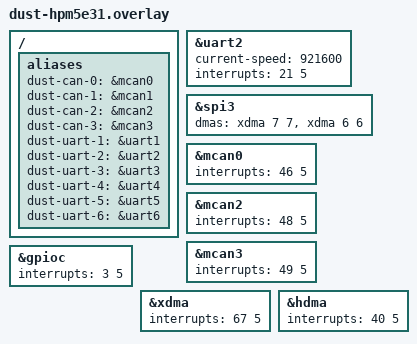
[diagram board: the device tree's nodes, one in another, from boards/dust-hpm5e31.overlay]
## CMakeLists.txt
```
# SPDX-License-Identifier: Apache-2.0

cmake_minimum_required(VERSION 3.20.0)

# ==============================================================================
# 1. Project Initialization
# ==============================================================================

include(${CMAKE_CURRENT_LIST_DIR}/cmake/prepare.cmake)

find_package(Zephyr REQUIRED HINTS $ENV{ZEPHYR_BASE})
project(dust_ethercat_slave)


set(CMAKE_EXPORT_COMPILE_COMMANDS ON)

# ==============================================================================
# 2. Paths and Dependencies
# ==============================================================================

set(ADAPTER_SSC_DIR
    "${ADAPTER_ROOT}/src/ssc_generated"
    CACHE PATH "Licensed SSC 5.13 generated source directory"
)

set(HPM_PHY_DIR
    "${HPM_SUPPORT_DIR}/samples/ecat/Middleware/ESC"
)
set(HPM_PHY_BOARD_DIR
    "${HPM_SUPPORT_DIR}/samples/ecat/EtherCAT/bsp"
)

set(GENERATED_DIR "${CMAKE_CURRENT_BINARY_DIR}/generated")
set(SSC_GATEWAY_DIR "${CMAKE_CURRENT_BINARY_DIR}/ssc_gateway")
set(ADAPTER_CAN_CONFIG
    "${ADAPTER_ROOT}/config/can_devices.yaml"
    CACHE FILEPATH "MCU CAN device/protection configuration"
)
if(CONFIG_ECAT_CAN_ISOLATION)
    # Keep the diagnostic topology and protection whitelist inseparable.
    set(ADAPTER_CAN_CONFIG "${ADAPTER_ROOT}/config/can_isolation.yaml")
endif()
set(PDO_SCHEMA "${ADAPTER_ROOT}/config/pdo_schema.yaml")

find_package(Python3 COMPONENTS Interpreter REQUIRED)

# ==============================================================================
# 3. Dependency Validation
# ==============================================================================

set(SSC_REQUIRED_FILES
    ecat_def.h
    ecatslv.c
    ecatappl.c
    sampleappl.c
    sampleappl.h
    applInterface.h
    eeprom.h
)
foreach(required_file IN LISTS SSC_REQUIRED_FILES)
    if(NOT EXISTS "${ADAPTER_SSC_DIR}/${required_file}")
        message(FATAL_ERROR
            "SSC source missing: ${required_file}. "
            "Import your licensed configured sources with tools/import_ssc.py; "
            "see docs/ethercat.md")
    endif()
endforeach()

file(READ "${ADAPTER_SSC_DIR}/ecat_def.h" SSC_CONFIG_CONTENT)
if(SSC_CONFIG_CONTENT MATCHES "#define[ \t]+DC_SUPPORTED[ \t]+1")
    message(FATAL_ERROR "FreeRun requires DC_SUPPORTED=0 SSC sources")
endif()

if(NOT EXISTS "${HPM_PHY_DIR}/hpm5e31_phy.c")
    message(FATAL_ERROR
        "HPM5E31 PHY implementation missing; update hpm_support to west.yml "
        "revision")
endif()

# ==============================================================================
# 4. Code Generation（构建期生成，生成物是常量唯一来源）
# ==============================================================================

file(MAKE_DIRECTORY "${GENERATED_DIR}" "${SSC_GATEWAY_DIR}")

set(PDO_SCHEMA_HEADER "${GENERATED_DIR}/pdo_schema.hpp")
add_custom_command(
    OUTPUT "${PDO_SCHEMA_HEADER}"
    COMMAND ${Python3_EXECUTABLE} "${ADAPTER_ROOT}/tools/generate_pdo_schema.py"
            --schema "${PDO_SCHEMA}" --output "${PDO_SCHEMA_HEADER}"
    DEPENDS "${ADAPTER_ROOT}/tools/generate_pdo_schema.py" "${PDO_SCHEMA}"
    COMMENT "Generating pdo_schema.hpp"
    VERBATIM)

set(CAN_PROFILE_HEADER "${GENERATED_DIR}/can_profile_generated.hpp")
add_custom_command(
    OUTPUT "${CAN_PROFILE_HEADER}"
    COMMAND ${Python3_EXECUTABLE} "${ADAPTER_ROOT}/tools/generate_can_profile.py"
            --input "${ADAPTER_CAN_CONFIG}" --output "${CAN_PROFILE_HEADER}"
    DEPENDS "${ADAPTER_ROOT}/tools/generate_can_profile.py"
            "${ADAPTER_CAN_CONFIG}"
    COMMENT "Generating can_profile_generated.hpp"
    VERBATIM)

add_custom_target(dust_pdo_schema DEPENDS "${PDO_SCHEMA_HEADER}")
add_custom_target(dust_can_profile DEPENDS "${CAN_PROFILE_HEADER}")

set_property(DIRECTORY APPEND PROPERTY CMAKE_CONFIGURE_DEPENDS
    "${ADAPTER_ROOT}/config/ethercat_gateway.json"
    "${ADAPTER_ROOT}/tools/generate_gateway_esi.py")
execute_process(
    COMMAND ${Python3_EXECUTABLE} "${ADAPTER_ROOT}/tools/generate_gateway_esi.py"
            --output "${SSC_GATEWAY_DIR}"
    COMMAND_ERROR_IS_FATAL ANY)

# ==============================================================================
# 5. SSC Source Staging
# ==============================================================================

file(GLOB SSC_INPUTS CONFIGURE_DEPENDS
    "${ADAPTER_SSC_DIR}/*.c" "${ADAPTER_SSC_DIR}/*.h")
set(SSC_SOURCES)
set(SSC_EXCLUDED_FILES sampleappl.c sampleappl.h eeprom.h)
foreach(input_file IN LISTS SSC_INPUTS)
    get_filename_component(file_name "${input_file}" NAME)
    if(file_name IN_LIST SSC_EXCLUDED_FILES)
        continue()
    endif()
    configure_file("${input_file}" "${SSC_GATEWAY_DIR}/${file_name}" COPYONLY)
    if(file_name MATCHES "\\.c$")
        list(APPEND SSC_SOURCES "${SSC_GATEWAY_DIR}/${file_name}")
    endif()
endforeach()
configure_file("${ADAPTER_ROOT}/src/adapters/ethercat_ssc/sampleappl.h"
               "${SSC_GATEWAY_DIR}/sampleappl.h" COPYONLY)

# ==============================================================================
# 6. Layered Static Libraries（依赖方向由链接图强制）
# ==============================================================================

# 6.1 domain: 协议/策略逻辑，链接 Zephyr 接口以统一 libc/stdint 配置。
add_library(dust_domain OBJECT
    "${ADAPTER_ROOT}/src/domain/protocol/wire.cpp"
    "${ADAPTER_ROOT}/src/domain/protocol/can_channel.cpp"
    "${ADAPTER_ROOT}/src/domain/protocol/uart_channel.cpp"
    "${ADAPTER_ROOT}/src/domain/protocol/codec.cpp"
    "${ADAPTER_ROOT}/src/domain/pdo/layout.cpp"
    "${ADAPTER_ROOT}/src/domain/pdo/pdo_dictionary.cpp"
    "${ADAPTER_ROOT}/src/domain/protocol/session.cpp"
    "${ADAPTER_ROOT}/src/domain/can/can_service.cpp"
    "${ADAPTER_ROOT}/src/domain/uart/uart_service.cpp"
    "${ADAPTER_ROOT}/src/domain/protection/protection.cpp"
)
target_include_directories(dust_domain
    PUBLIC "${ADAPTER_ROOT}/src"
    PRIVATE "${GENERATED_DIR}")
target_compile_features(dust_domain PUBLIC cxx_std_17)
target_compile_options(dust_domain PRIVATE -fno-exceptions -fno-rtti)
# 统一 libc/stdint 配置：与 app/adapters 使用同一套 stdint 定义。
target_link_libraries(dust_domain PRIVATE zephyr_interface)
add_dependencies(dust_domain dust_pdo_schema)

# 6.2 drivers: 窄硬件原语 + CAN/UART/IMU 设备类。
add_library(dust_drivers OBJECT
    "${ADAPTER_ROOT}/src/drivers/can/can_driver.cpp"
    "${ADAPTER_ROOT}/src/drivers/uart/uart_driver.cpp"
    "${ADAPTER_ROOT}/src/drivers/uart/uart_receive.cpp"
    "${ADAPTER_ROOT}/src/drivers/spi_imu/imu_sensor.cpp"
    "${ADAPTER_ROOT}/src/drivers/spi_imu/imu_source.cpp"
    "${ADAPTER_ROOT}/src/drivers/can/can_bus.cpp"
    "${ADAPTER_ROOT}/src/drivers/uart/uart_port.cpp"
    "${ADAPTER_ROOT}/src/drivers/pwm/outputs.cpp"
)
if(CONFIG_BUZZER OR CONFIG_BOARD_OUTPUTS)
    target_sources(dust_drivers PRIVATE
        "${ADAPTER_ROOT}/src/drivers/pwm/board_pwm.c")
endif()
if(CONFIG_BUZZER)
    target_sources(dust_drivers PRIVATE
        "${ADAPTER_ROOT}/src/drivers/pwm/buzzer.c")
endif()
target_include_directories(dust_drivers PUBLIC "${ADAPTER_ROOT}/src")
target_link_libraries(dust_drivers PRIVATE zephyr_interface)

# 6.3 adapters: ESC/SSC/board 适配。
add_library(dust_adapters OBJECT
    "${ADAPTER_ROOT}/src/adapters/esc/esc_regs.c"
    "${ADAPTER_ROOT}/src/adapters/esc/esc_boot.c"
    "${ADAPTER_ROOT}/src/adapters/esc/sii.c"
    "${ADAPTER_ROOT}/src/adapters/ethercat_ssc/ssc_stack.cpp"
    "${ADAPTER_ROOT}/src/adapters/ethercat_ssc/ssc_callbacks.cpp"
    "${ADAPTER_ROOT}/src/adapters/ethercat_ssc/ssc_dictionary.cpp"
    "${ADAPTER_ROOT}/src/adapters/ethercat_ssc/io_coordinator.cpp"
    "${ADAPTER_ROOT}/src/adapters/ethercat_ssc/feedback.cpp"
    "${ADAPTER_ROOT}/src/adapters/ethercat_ssc/layout_service.cpp"
    "${HPM_PHY_DIR}/hpm5e31_phy.c"
    ${SSC_SOURCES}
)
target_include_directories(dust_adapters
    PUBLIC "${ADAPTER_ROOT}/src"
    PRIVATE
        "${GENERATED_DIR}"
        "${SSC_GATEWAY_DIR}"
        "${HPM_PHY_DIR}"
        "${HPM_PHY_BOARD_DIR}"
)
add_dependencies(dust_adapters dust_can_profile dust_pdo_schema)
target_compile_options(dust_adapters PRIVATE
    "-include${SSC_GATEWAY_DIR}/gateway_config.h")
set_source_files_properties(${SSC_SOURCES}
    PROPERTIES COMPILE_OPTIONS
        "-Wno-unused-parameter;-Wno-sign-compare;-Wno-implicit-fallthrough")
target_link_libraries(dust_adapters
    PUBLIC dust_domain
    PRIVATE dust_drivers zephyr_interface)

# ==============================================================================
# 7. Application
# ==============================================================================

target_sources(app PRIVATE
    "${ADAPTER_ROOT}/src/main.cpp"
    "${ADAPTER_ROOT}/src/composition.cpp"
    "${ADAPTER_ROOT}/src/identity.cpp"
    "${ADAPTER_ROOT}/src/lifecycle.cpp"
    "${ADAPTER_ROOT}/src/scheduler.cpp"
)
target_include_directories(app PRIVATE
    "${ADAPTER_ROOT}/src"
    "${GENERATED_DIR}"
    "${SSC_GATEWAY_DIR}")
target_sources(app PRIVATE
    $<TARGET_OBJECTS:dust_domain>
    $<TARGET_OBJECTS:dust_drivers>
    $<TARGET_OBJECTS:dust_adapters>)


# 库目标也要等待 Zephyr 生成头（offsets/version 等），否则会在
# zephyr_generated_headers 完成前编译 .obj。
add_dependencies(dust_drivers zephyr_generated_headers)
add_dependencies(dust_adapters zephyr_generated_headers)
add_dependencies(app zephyr_generated_headers dust_can_profile)
```

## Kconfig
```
source "Kconfig.zephyr"

config ONBOARD_IMU_RAW
    bool "Acquire raw HXY onboard IMU bursts"
    default n

config ECAT_ALLOW_MISSING_ONBOARD_IMU
    bool "Allow the fixed DTG1 IMU slot without an installed sensor"
    depends on !ONBOARD_IMU_RAW
    default n
    help
      Explicit unwelded-board profile only. Preserve the 28-byte physical slot,
      but do not reserve logical IMU resources or publish sensor samples.
      CAN, HI91, mapping signatures and output protection remain mandatory.

config ONBOARD_IMU_SPI_FREQUENCY_HZ
    int "Onboard IMU SPI frequency"
    default 8000000
    range 100000 24000000
    depends on ONBOARD_IMU_RAW

config DMA_BUFFER_ALIGNMENT
    int "DMA buffer alignment in bytes (power of two)"
    default 4
    range 4 4096

config BUZZER
    bool "Board buzzer on PWM0 channel 1"
    depends on PWM && BOARD_DUST_HPM5E31
    default n

config BOARD_OUTPUTS
    bool "Board LEDs, buzzer and IMU heater"
    depends on PWM && GPIO
    default n

config IMU_HEATER_ENABLE
    bool "Enable IMU heater output (requires bench tuning)"
    depends on BOARD_OUTPUTS
    default n

config IMU_TARGET_C
    int "IMU target temperature in Celsius"
    default 45
    range 25 50

config IMU_HEATER_PERIOD_MS
    int "Heater PID control period in milliseconds"
    default 10
    range 1 1000
    help
      Period of the temperature control loop; 10 ms is 100 Hz.

config IMU_HEATER_KP_MILLI
    int "Heater proportional gain, multiplied by 1000"
    default 100
    range 0 1000

config IMU_HEATER_KI_MILLI
    int "Heater integral gain, multiplied by 1000"
    default 5
    range 0 1000

config IMU_HEATER_KD_MILLI
    int "Heater derivative gain, multiplied by 1000"
    default 0
    range 0 1000

config IMU_HEATER_MAX_PERMILLE
    int "Maximum heater duty in permille"
    default 1000
    range 0 1000

config ECAT_UART_RX_DMA_BYTES
    int "UART receive DMA buffer size"
    default 128
    range 64 512

config ECAT_UART2_IDLE_US
    int "UART2 receive idle threshold in microseconds"
    default 80
    range 20 200

config ECAT_SOURCE_ARRIVAL_STATS
    bool "Collect source arrival intervals for external acceptance"
    depends on MCAN_HPMICRO && ONBOARD_IMU_RAW
    select HPM_MCAN_RX_TIMING
    default n
    help
      Opt-in CAN SOF/callback and IMU DRDY/DMA-completion arrival statistics.
      Freeze before Stop protection traffic and report only after stopping.
      Disabled builds contain no collection or reporting hot path.

config ECAT_CAN_ISOLATION
    bool "Isolate wheel CAN buses for matched host acceptance"
    depends on MCAN_HPMICRO
    default n
    help
      DTG2 test profile: right wheel CAN1, left wheel CAN2, joints CAN0/CAN3.
      Requires matching wiring, protection configuration and host profile.
```

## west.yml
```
# SPDX-License-Identifier: Apache-2.0
manifest:
  version: "1.0"
  remotes:
    - name: hpmicro
      url-base: https://github.com/hpmicro
    - name: dust
      url-base: https://github.com/HNUST-Dust
    - name: upstream
      url-base: https://github.com/zephyrproject-rtos
    - name: usb-fork
      url-base: https://github.com/NoneOfEver
  projects:
    - name: zephyr
      remote: hpmicro
      revision: 8c6db8fa778cf90eb93e823e513a1ab97703711d
      west-commands: scripts/west-commands.yml
    - name: hpm_support
      remote: dust
      revision: d1e9fbfbdca40c3ecc965795917735cb92bd6fd2
    - name: sdk_env
      remote: usb-fork
      revision: 7b8cb8bb2f04f52353a6429bffb024f0a2867876
    - name: CherryUSB
      remote: usb-fork
      path: cherry_usb
      revision: 50c7e9085801e24d2d0991d0c4c1609fdbcfb90a
    - name: segger
      remote: upstream
      revision: b011c45b585e097d95d9cf93edf4f2e01588d3cd
  self:
    path: dust-adapter
    west-commands: scripts/west-commands.yml
```

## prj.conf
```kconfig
CONFIG_BOOT_BANNER=n
CONFIG_CONSOLE=y
CONFIG_PRINTK=y
CONFIG_SERIAL=y
CONFIG_UART_CONSOLE=n
CONFIG_STDOUT_CONSOLE=n
CONFIG_USE_SEGGER_RTT=y
CONFIG_RTT_CONSOLE=y
CONFIG_SEGGER_RTT_BUFFER_SIZE_UP=16384
CONFIG_LOG=n
CONFIG_REBOOT=n
CONFIG_MAIN_STACK_SIZE=8192
CONFIG_HEAP_MEM_POOL_SIZE=4096
CONFIG_FLASH=y
CONFIG_FLASH_MAP=y
CONFIG_HPM_ESC=y
# Aligned PDRAM transfers; set n for the original byte-access comparison.
CONFIG_HPM_ESC_PDRAM_WORD_ACCESS=y

# Keep the first SSC bring-up simple. DC/SYNC interrupts are not required for
# the FreeRun DTC1 gateway test.
CONFIG_ISR_STACK_SIZE=4096

# Adapter firmware has no local filesystem or FatFs dependency.
CONFIG_FILE_SYSTEM=n

# HPM5E31 板载 IMU 使用 SPI3 采集原始突发（加热输出仍关闭）。
CONFIG_PWM=y
CONFIG_BUZZER=y
CONFIG_SPI=y
CONFIG_SPI_ASYNC=y
CONFIG_DMA=y
CONFIG_SPI_HPM_SPI_DMA=y
CONFIG_ONBOARD_IMU_RAW=y

# DTC1 协议核心与 SSC 应用适配使用 C++17。
CONFIG_CPP=y
CONFIG_STD_CPP17=y
CONFIG_REQUIRES_FULL_LIBCPP=y

# 5E31 使用原生 RX idle 发布部分 DMA 缓冲区；后端统一配置 1 ms idle 并启动业务端口。
CONFIG_UART_ASYNC_API=y
CONFIG_UART_INTERRUPT_DRIVEN=y
CONFIG_UART_HPMICRO_RX_NATIVE_IDLE=y

# 后端需要动态配置 DBUS 8E2，并用预留 Flash 区保存跨上电启动计数。
CONFIG_UART_USE_RUNTIME_CONFIGURE=y
CONFIG_NVS=y
CONFIG_NVS_DATA_CRC=y
CONFIG_SYS_CLOCK_TICKS_PER_SEC=10000
# HPM 启动头仍从 Flash 0 开始；链接区止于 0xd0000，避免代码增长覆盖 NVS/诊断区。
CONFIG_ROM_END_OFFSET=0x30000

# NVS 扫描及 ROM Flash 调用也在主线程，启用栈边界检测。
CONFIG_STACK_SENTINEL=y
CONFIG_INIT_STACKS=y

# The SSC owner, CAN transmit, IMU acquisition and HI91 parser use bounded workers.
CONFIG_MAIN_THREAD_PRIORITY=0
CONFIG_THREAD_NAME=y

# DTG1 uses SM2 synchronization and complete latest device snapshots.
# Preserve byte-equivalent publication optimization with the table digest.

# Board outputs: buzzer is already enabled; add the IMU heater PID loop.
# The heater runs at 20 ms with a 45 C target (see the PID constants below).
CONFIG_GPIO=y
CONFIG_BOARD_OUTPUTS=y
CONFIG_IMU_HEATER_ENABLE=y
CONFIG_IMU_TARGET_C=45
CONFIG_IMU_HEATER_KP_MILLI=100
CONFIG_IMU_HEATER_KI_MILLI=20
CONFIG_IMU_HEATER_KD_MILLI=0
CONFIG_IMU_HEATER_MAX_PERMILLE=1000
CONFIG_IMU_HEATER_PERIOD_MS=10

# DTG1 release runtime. Test counters require an explicit acceptance overlay.
CONFIG_ECAT_UART_RX_DMA_BYTES=128
CONFIG_ECAT_UART2_IDLE_US=80
```

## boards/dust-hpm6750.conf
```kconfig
# SPDX-License-Identifier: Apache-2.0

CONFIG_HPM67_DOUBLE_PRECISION_FPU=y
CONFIG_FPU=y
CONFIG_FPU_SHARING=y

CONFIG_SPI_HPMICRO=y
CONFIG_SPI_HPM_SPI_DMA=y
CONFIG_SPI_HPM_SPI_INTERRUPT=n
CONFIG_HPM_PLIC_PRIORITY_NESTING=y
CONFIG_HPM_PLIC_MAX_NESTING_DEPTH=4
CONFIG_WBR_CONTROL_ONBOARD_IMU_RAW=y
CONFIG_DUST_DMA_BUFFER_ALIGNMENT=64
CONFIG_PWM=y
CONFIG_DUST_BOARD_OUTPUTS=y
CONFIG_DUST_IMU_HEATER_ENABLE=y
```

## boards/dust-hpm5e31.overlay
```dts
/* SPDX-License-Identifier: Apache-2.0 */
/ { aliases {
    dust-can-0 = &mcan0; dust-can-1 = &mcan1;
    dust-can-2 = &mcan2; dust-can-3 = &mcan3;
    dust-uart-1 = &uart1; dust-uart-2 = &uart2;
    dust-uart-3 = &uart3; dust-uart-4 = &uart4;
    dust-uart-5 = &uart5; dust-uart-6 = &uart6;
}; };

/* HI91 实机使用 921600 baud；通用板级默认值保持不变。 */
&uart2 {
    current-speed = <921600>;
};

/* 板载 HXY IMU 使用 SPI3；CS=PC21、DRDY=PC18 由板级 DTS 别名提供。 */
&spi3 {
    status = "okay";
    dmas = <&xdma 7 7>, <&xdma 6 6>;
    dma-names = "tx", "rx";
};

/* XDMA 0..5 belong to UART4..6; channels 6/7 serve SPI3 RX/TX. */

/* DTG1 acquisition and feedback IRQ priorities. */
/* Complete acquisition/feedback events before the ESC PDI handler. */
&mcan0 { interrupts = <46 5>; };
&mcan2 { interrupts = <48 5>; };
&mcan3 { interrupts = <49 5>; };
&gpioc { interrupts = <3 5>; };
&xdma { interrupts = <67 5>; };
&uart2 { interrupts = <21 5>; };
&hdma { interrupts = <40 5>; };
```

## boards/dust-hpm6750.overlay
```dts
/ {
    aliases {
        dust-uart-1 = &uart10;
        dust-uart-2 = &uart2;
        dust-uart-3 = &uart3;
        dust-uart-4 = &uart11;
        dust-uart-5 = &uart12;
        dust-uart-6 = &uart15;
        dust-can-0 = &can0;
        dust-can-1 = &can1;
        dust-can-2 = &can2;
        dust-can-3 = &can3;
    };
};

&uart11 {
    dmas = <&xdma 4 30>, <&xdma 5 31>;
    dma-names = "rx", "tx";
};
&uart15 {
    dmas = <&xdma 6 38>, <&xdma 7 39>;
    dma-names = "rx", "tx";
};
/ {
    aliases { dust-buzzer = &dust_buzzer; };
    dust_outputs {
        compatible = "pwm-leds";
        dust_buzzer: buzzer { pwms = <&pwm0 6 PWM_HZ(2000) PWM_POLARITY_NORMAL>; };
    };
};

&pinctrl {
    dust_led_pins: dust_led_pins {
        group0 {
            pinmux = <HPMICRO_PINMUX(HPMICRO_PIN(HPMICRO_PORTC, 12), IOC_TYPE_IOC, 0, 0)>,
                     <HPMICRO_PINMUX(HPMICRO_PIN(HPMICRO_PORTC, 13), IOC_TYPE_IOC, 0, 0)>,
                     <HPMICRO_PINMUX(HPMICRO_PIN(HPMICRO_PORTC, 16), IOC_TYPE_IOC, 0, 0)>;
        };
    };
};
&gpioc {
    pinctrl-0 = <&dust_led_pins>;
    pinctrl-names = "default";
};
```

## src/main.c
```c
/* SPDX-License-Identifier: Apache-2.0 */

#include <zephyr/kernel.h>
#include <zephyr/sys/printk.h>

#include "drivers/buzzer.h"
#include "ecat/runtime.h"

#if defined(CONFIG_BOARD_OUTPUTS)
extern int imu_heater_init(void);
#endif

int main(void) {
    if (ecat_runtime_init() != 0) {
        return 0;
    }

#if defined(CONFIG_BUZZER)
    const int buzzer_rc = buzzer_init();
    if (buzzer_rc) {
        printk("Buzzer init failed: %d\n", buzzer_rc);
    }
#endif

    const int start_rc = ecat_runtime_start();
    if (start_rc == -1) {
        printk("SSC MainInit failed\n");
        return 0;
    }
    if (start_rc != 0) {
        printk("DTC1 gateway initialization failed; IRQs remain disabled\n");
        return 0;
    }

#if defined(CONFIG_BOARD_OUTPUTS)
    /* Start the PID only after the IMU is sampling, so a slow first sample
     * cannot latch the heater fault. */
    const int heater_rc = imu_heater_init();
    if (heater_rc) {
        printk("IMU heater init failed: %d\n", heater_rc);
    }
#endif

    ecat_runtime_enable();
    printk("DUST HPM5E31 DTC1 LAB ready: VID=0 PID=0x44544331; CAN/UART IO "
           "installed\n");

    for (;;) {
        const ecat_step_t step = ecat_runtime_step();
        if (step == ECAT_STEP_FATAL) {
            return 0;
        }
        /* Active 时避免 100 us 系统 tick 取整形成额外周期延迟；ISR 仍可抢占。 */
        if (step == ECAT_STEP_ACTIVE) {
            k_busy_wait(10);
        } else {
            k_usleep(100);
        }
    }
}
```

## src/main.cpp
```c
/* SPDX-License-Identifier: Apache-2.0 */

#include "composition.hpp"


extern "C" int main(void) {
    static app::Composition composition;
    if (composition.Init() != 0) {
        return 0;
    }
    composition.Run();
    return 0;
}
```

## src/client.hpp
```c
/* SPDX-License-Identifier: Apache-2.0 */
/** @file client.hpp
 * @brief Host request builders; caller owns transport and sequence allocation.
 */
#pragma once
#include <stdexcept>

#include "protocol.hpp"

namespace dust {
// Allocation-free packet builders. Transport ownership and sequence allocation
// belong to the caller.
/**
 * @brief Build a zero-padded request; caller supplies kind, sequence and
 * session.
 */
inline wire::Request Control(wire::Kind kind, uint32_t sequence,
                             uint32_t session) {
    wire::Request request{};
    wire::Header(request.data(), kind, sequence, session);
    return request;
}
/**
 * @brief Build a lease/protection request; actions may be null only when count
 * is zero.
 * @throws std::invalid_argument If lease, count or action encoding is invalid.
 */
inline wire::Request SafetyConfiguration(uint32_t sequence, uint32_t session,
                                         uint32_t lease_us,
                                         const wire::Record* actions,
                                         size_t count) {
    if (count > wire::kMaxRecords || (count && !actions) || lease_us < 1000 ||
        lease_us > 1000000)
        throw std::invalid_argument("Invalid adapter safety configuration");
    auto request = Control(wire::Kind::ConfigureSafety, sequence, session);
    request[10] = uint8_t(count);
    wire::Put32(request.data() + 16, lease_us);
    for (size_t i = 0; i < count; ++i)
        wire::Encode(request.data() + 32 + 16 * i, actions[i]);
    if (!wire::ValidRecords(request, true))
        throw std::invalid_argument("Invalid stop action");
    return request;
}
// Selects the MCU's compiled protection table; zero count does not disable it.
/**
 * @brief Select compiled MCU protection without replacing or deleting it.
 * @throws std::invalid_argument If lease_us is outside the wire range.
 */
inline wire::Request SelectFirmwareSafety(uint32_t sequence, uint32_t session,
                                          uint32_t lease_us) {
    return SafetyConfiguration(sequence, session, lease_us, nullptr, 0);
}
/**
 * @brief Build a CAN batch; records may be null only for an empty batch.
 * @throws std::invalid_argument If count, pointer or record encoding is
 * invalid.
 */
inline wire::Request CanTransmit(uint32_t sequence, uint32_t session,
                                 const wire::Record* records, size_t count) {
    if (count > wire::kMaxRecords || (count && !records))
        throw std::invalid_argument("Invalid CAN batch");
    auto request = Control(wire::Kind::Transmit, sequence, session);
    request[10] = uint8_t(count);
    for (size_t i = 0; i < count; ++i)
        wire::Encode(request.data() + 32 + 16 * i, records[i]);
    if (!wire::ValidRecords(request))
        throw std::invalid_argument("Invalid CAN record");
    return request;
}
/**
 * @brief Build a UART request by copying length bytes from bytes.
 * @throws std::invalid_argument If port, pointer or payload length is invalid.
 */
inline wire::Request UartWrite(uint32_t sequence, uint32_t session,
                               uint8_t port, const uint8_t* bytes,
                               size_t length) {
    if (port < 1 || port > 3 || !length || length > wire::kMaxUartWrite ||
        !bytes)
        throw std::invalid_argument("Invalid UART write");
    auto request = Control(wire::Kind::UartWrite, sequence, session);
    request[10] = port;
    request[11] = uint8_t(length);
    std::memcpy(request.data() + 32, bytes, length);
    return request;
}
}  // namespace dust
```

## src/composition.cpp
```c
/* SPDX-License-Identifier: Apache-2.0 */

#include "composition.hpp"

#include <array>
#include <cstddef>

#include <zephyr/device.h>
#include <zephyr/devicetree.h>
#include <zephyr/kernel.h>
#include <zephyr/sys/printk.h>
#include <zephyr/sys/util.h>

#include <can_profile_generated.hpp>
#include <gateway_config.h>

#include "adapters/esc/esc_hw.h"
#include "common/types.hpp"
#include "common/device_pdo.hpp"
#include "domain/can/can_topology.hpp"
#include "identity.hpp"
#if defined(CONFIG_BUZZER)
#include "drivers/pwm/buzzer.h"
#endif

namespace app {
namespace {
constexpr int kCanWorkerPriority = K_PRIO_COOP(CONFIG_NUM_COOP_PRIORITIES - 1);
// Share priority with bounded sensor workers so ACK/watchdog work cannot starve.
constexpr int kPdoWorkerPriority = K_PRIO_PREEMPT(0);
constexpr int kImuWorkerPriority = K_PRIO_PREEMPT(0);


K_THREAD_STACK_DEFINE(imu_worker_stack, 2048);
k_thread imu_worker_thread;

void ImuWorkerLoop(void* context, void*, void*) {
    auto& feedback = *static_cast<ecat::FeedbackAggregator*>(context);
    for (;;) {
        feedback.PollSensors();
        // DMA/DRDY events provide pacing; yield to equal-priority maintenance
        // without imposing another tick before a completed sample is published.
        k_yield();
        feedback.WaitForImuEvent();
    }
}

K_THREAD_STACK_DEFINE(pdo_worker_stack, 3072);
k_thread pdo_worker_thread;

void PdoWorkerLoop(void* context, void*, void*) {
    static_cast<ecat::SscStack*>(context)->RunPdoWorker();
}

K_THREAD_STACK_ARRAY_DEFINE(can_transmit_stacks, dust::device_pdo::kTxBuses.size(), 2048);
k_thread can_transmit_threads[dust::device_pdo::kTxBuses.size()];

void CanTransmitLoop(void* context, void* side, void*) {
    static_cast<ecat::SscStack*>(context)->RunCanTransmit(uintptr_t(side));
}

struct BoardData {
    std::array<ecat::CanBusConfig, 4> can_buses{};
    size_t can_bus_count = 0;

    std::array<ecat::UartPortConfig, 6> uart_ports{};

    std::array<ecat::CanFilterConfig, 64> filters{};
    size_t filter_count = 0;

    std::array<ecat::CanTxAddress, 64> tx_addresses{};
    size_t tx_count = 0;

    std::array<ecat::CanFrame, 32> protection_frames{};
    size_t protection_count = 0;

    ecat::CanTopology can_topology{};
    ecat::HeaterConfig heater{};
    ecat::SscBoardConfig ssc{};
};

const device* CanDevice(uint8_t channel) {
    switch (channel) {
        case 0:
            return DEVICE_DT_GET(DT_ALIAS(dust_can_0));
        case 1:
            return DEVICE_DT_GET(DT_ALIAS(dust_can_1));
        case 2:
            return DEVICE_DT_GET(DT_ALIAS(dust_can_2));
        default:
            return DEVICE_DT_GET(DT_ALIAS(dust_can_3));
    }
}

const device* UartDevice(uint8_t index) {
    switch (index) {
        case 0:
            return DEVICE_DT_GET(DT_ALIAS(dust_uart_1));
        case 1:
            return DEVICE_DT_GET(DT_ALIAS(dust_uart_2));
        case 2:
            return DEVICE_DT_GET(DT_ALIAS(dust_uart_3));
        case 3:
            return DEVICE_DT_GET(DT_ALIAS(dust_uart_4));
        case 4:
            return DEVICE_DT_GET(DT_ALIAS(dust_uart_5));
        default:
            return DEVICE_DT_GET(DT_ALIAS(dust_uart_6));
    }
}

BoardData BuildBoard() {
    BoardData data;

    for (const auto& bus : can_profile::kBuses) {
        if (data.can_bus_count == data.can_buses.size()) {
            break;
        }
        data.can_buses[data.can_bus_count++] = {CanDevice(bus.channel),
                                               bus.channel, bus.bitrate};
    }

    for (size_t index = 0; index < data.uart_ports.size(); ++index) {
        data.uart_ports[index] = {UartDevice(uint8_t(index)), uint8_t(index),
                                  index == 4, index == 4};
    }

    for (const auto& filter : can_profile::kReceiveFilters) {
        if (data.filter_count == data.filters.size()) {
            break;
        }
        data.filters[data.filter_count++] = {filter.channel, filter.id, 0x7ff};
    }

    for (const auto& address : can_profile::kTransmitAddresses) {
        if (data.tx_count == data.tx_addresses.size()) {
            break;
        }
        data.tx_addresses[data.tx_count++] = {address.channel, address.id,
                                             address.flags};
    }

    for (const auto& frame : can_profile::kProtectionFrames) {
        if (data.protection_count == data.protection_frames.size()) {
            break;
        }
        ecat::CanFrame value;
        value.bus = frame.channel;
        value.length = frame.length;
        value.id = frame.id;
        for (size_t i = 0; i < value.data.size(); ++i) {
            value.data[i] = frame.data[i];
        }
        data.protection_frames[data.protection_count++] = value;
    }

    data.can_topology.command_timeout_us = can_profile::kCommandTimeoutUs;
    data.can_topology.protection_signature =
        can_profile::kProtectionSignature;
    data.can_topology.protect_on_boot = can_profile::kProtectOnBoot;

#if defined(CONFIG_BOARD_OUTPUTS)
    data.heater.enabled = IS_ENABLED(CONFIG_IMU_HEATER_ENABLE);
    data.heater.target_c = float(CONFIG_IMU_TARGET_C);
    data.heater.kp = float(CONFIG_IMU_HEATER_KP_MILLI) / 1000.0f;
    data.heater.ki = float(CONFIG_IMU_HEATER_KI_MILLI) / 1000.0f;
    data.heater.kd = float(CONFIG_IMU_HEATER_KD_MILLI) / 1000.0f;
    data.heater.max_duty =
        float(CONFIG_IMU_HEATER_MAX_PERMILLE) / 1000.0f;
    data.heater.period_ms = CONFIG_IMU_HEATER_PERIOD_MS;
#endif

    data.ssc.rx_max = MAX_PD_OUTPUT_SIZE;
    data.ssc.tx_max = MAX_PD_INPUT_SIZE;
    data.ssc.ram_end = ECAT_RAM_END;
    data.ssc.rx_address = ECAT_RX_ADDRESS;
    data.ssc.tx_address = ECAT_TX_ADDRESS;
    return data;
}

const BoardData& Board() {
    static BoardData data = BuildBoard();
    /* 拓扑中的指针指向本静态实例的数组，初始化后再接线。 */
    data.can_topology.tx_addresses = data.tx_addresses.data();
    data.can_topology.tx_count = data.tx_count;
    data.can_topology.filters = data.filters.data();
    data.can_topology.filter_count = data.filter_count;
    data.can_topology.protection_frames = data.protection_frames.data();
    data.can_topology.protection_count = data.protection_count;
    return data;
}

}  // namespace

Composition::Composition()
    : can_bus_(Board().can_buses.data(), Board().can_bus_count),
      uart_port_(Board().uart_ports.data(), Board().uart_ports.size()),
      outputs_(Board().heater),
      session_(0),
      can_(can_bus_, Board().can_topology),
      uart_(uart_port_),
      feedback_(can_, uart_, imu_),
      io_(can_, uart_, feedback_),
      protection_(session_, can_, uart_),
      stack_(session_, layout_, io_, protection_, Board().ssc),
      lifecycle_(stack_, &ecat::AllocateBootIdentity, session_, protection_,
                 io_),
      scheduler_(lifecycle_, stack_, session_, io_, feedback_, outputs_) {}

int Composition::Init() {
    if (esc_init() != 0) {
        printk("EtherCAT ESC init failed\n");
        return -1;
    }
#if defined(CONFIG_BUZZER)
    const int buzzer_rc = buzzer_init();
    if (buzzer_rc) {
        printk("Buzzer init failed: %d\n", buzzer_rc);
    }
#endif

    can_.AttachFaultSink(protection_.Sink());
    uart_.AttachFaultSink(protection_.Sink());
    io_.AttachFaultSink(protection_.Sink());

    if (lifecycle_.Boot() != 0) {
        printk("Gateway boot failed\n");
        return -1;
    }
    if (outputs_.Init() != 0) {
        printk("Board outputs init failed\n");
    }
    lifecycle_.Enable();
    printk("DUST HPM5E31 DTC1 LAB ready: VID=0 PID=0x44544331; CAN/UART IO "
           "installed\n");
    return 0;
}

void Composition::Run() {
    k_thread_priority_set(k_current_get(), K_PRIO_PREEMPT(4));
    k_thread_create(&pdo_worker_thread, pdo_worker_stack,
                    K_THREAD_STACK_SIZEOF(pdo_worker_stack), PdoWorkerLoop,
                    &stack_, nullptr, nullptr, kPdoWorkerPriority, 0, K_NO_WAIT);
    for (unsigned side = 0; side < dust::device_pdo::kTxBuses.size(); ++side) {
        k_thread_create(&can_transmit_threads[side], can_transmit_stacks[side],
                        K_THREAD_STACK_SIZEOF(can_transmit_stacks[side]), CanTransmitLoop,
                        &stack_, reinterpret_cast<void*>(uintptr_t(side)), nullptr,
                        kCanWorkerPriority, 0, K_NO_WAIT);
    }
    k_thread_create(&imu_worker_thread, imu_worker_stack,
                    K_THREAD_STACK_SIZEOF(imu_worker_stack), ImuWorkerLoop,
                    &feedback_, nullptr, nullptr, kImuWorkerPriority, 0, K_NO_WAIT);
    for (;;) {
        const ecat::Scheduler::Step step = scheduler_.RunOnce();
        if (step == ecat::Scheduler::Step::Fatal) {
            k_thread_abort(&pdo_worker_thread);
            k_thread_abort(&imu_worker_thread);
            for (auto& thread : can_transmit_threads) {
                k_thread_abort(&thread);
            }
            printk("Gateway fatal; IRQs remain disabled\n");
            return;
        }
        if (step == ecat::Scheduler::Step::Active) {
            k_busy_wait(10);
        } else {
            k_usleep(100);
        }
    }
}

}  // namespace app
```

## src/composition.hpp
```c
/* SPDX-License-Identifier: Apache-2.0 */

/* 组合根：单板静态资源、适配器与 domain 服务的装配位置。
 * 生成头/DTS 别名只在这里出现。 */
#pragma once

#include "adapters/ethercat_ssc/ssc_stack.hpp"
#include "drivers/can/can_bus.hpp"
#include "drivers/spi_imu/imu_source.hpp"
#include "drivers/pwm/outputs.hpp"
#include "drivers/uart/uart_port.hpp"
#include "scheduler.hpp"
#include "domain/can/can_service.hpp"
#include "adapters/ethercat_ssc/feedback.hpp"
#include "adapters/ethercat_ssc/io_coordinator.hpp"
#include "adapters/ethercat_ssc/layout_service.hpp"
#include "lifecycle.hpp"
#include "domain/protection/protection.hpp"
#include "domain/protocol/session.hpp"
#include "domain/uart/uart_service.hpp"

namespace app {

class Composition {
   public:
    Composition();
    int Init();
    void Run();

   private:
    ecat::CanBusPort can_bus_;
    ecat::UartPort uart_port_;
    ecat::ImuSource imu_;
    ecat::ZephyrOutputs outputs_;

    ecat::Session session_;
    ecat::LayoutService layout_;
    ecat::CanService can_;
    ecat::UartService uart_;
    ecat::FeedbackAggregator feedback_;
    ecat::IoCoordinator io_;
    ecat::ProtectionService protection_;

    ecat::SscStack stack_;
    ecat::LifecycleService lifecycle_;
    ecat::Scheduler scheduler_;
};

}  // namespace app
```

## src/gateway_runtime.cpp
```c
/* SPDX-License-Identifier: Apache-2.0 */

/**
 * @file gateway_runtime.cpp
 * @brief USB 请求处理、会话保护及外设转发协调。
 */
#include "gateway_runtime.hpp"

#include <zephyr/kernel.h>

#include <cstring>

#include "drivers/board_indicators.hpp"
#include "drivers/can_port.hpp"
#include "drivers/firmware_can_profile.hpp"
#include "drivers/imu_heater.hpp"
#include "drivers/uart_port.hpp"
#include "drivers/usb_transport.hpp"
#include "imu_reports.hpp"
#include "usb_reports.hpp"
#include "usb_session_policy.hpp"

namespace {
namespace wire = dust::wire;
using wire::UsbInPacket;

constexpr int kRequestPriority = 7;

wire::SessionPolicy usb_session_policy;
wire::UartStopAction uart_stop_actions[wire::kMaxRecords]{};
size_t uart_stop_count = 0;
uint32_t usb_report_capabilities = 0;
uint32_t rejected_usb_requests = 0;
uint32_t stop_errors = 0;
uint32_t usb_connection_epoch = 0;
wire::StopReason last_stop = wire::StopReason::None;

/**
 * @brief 返回单调微秒时间的低 32 位。
 */
uint32_t NowUs() {
    return k_cyc_to_us_floor64(k_cycle_get_64());
}

/**
 * @brief 为指定请求排队发送结果码和转发授权状态。
 */
void QueueUsbRequestResult(const wire::UsbOutRequest& request, int result) {
    const wire::UsbOutRequestView fields(request);
    wire::RequestResultReport result_report{};
    result_report.header.session_id = usb_session_policy.Session();
    result_report.request_sequence = fields.Sequence();
    result_report.request_kind = fields.MessageKind();
    result_report.armed = usb_session_policy.Armed();
    result_report.result_code = result;
    UsbInPacket reply{};
    wire::Encode(result_report, reply);
    gateway::QueueUsbReply(reply);
}

/**
 * @brief 停止发布，以保护帧替换 CAN 业务流量，并执行 UART 停止动作。
 */
void CloseSession(wire::StopReason reason) {
    // 先清除发布会话，防止旧外设记录进入
    // 新会话。
    gateway::SetUsbReportSession(0);
    // 保护表属于 MCU 配置，不是可随会话或主机丢弃的状态。
    const auto& frames = dust::can_profile::kProtectionFrames;
    if (platform::ReplaceCanTraffic(frames.data(), frames.size())) {
        ++stop_errors;
    }
    gateway::DiscardUartWrites();
    for (size_t i = 0; i < uart_stop_count; ++i) {
        const auto& action = uart_stop_actions[i];
        if (gateway::SubmitUart(action.channel, action.data, action.length)) {
            ++stop_errors;
        }
    }
    uart_stop_count = 0;
    usb_session_policy.Close();
    last_stop = reason;
}

/**
 * @brief 校验并安装会话 UART 动作和租约；返回零或负 errno。
 */
int ConfigureSafety(const wire::UsbOutRequest& request) {
    if (!dust::can_profile::AcceptsSafetyRequest(request)) {
        return -EACCES;
    }
    wire::ConfigureSafetyRequest configuration{};
    if (!wire::Decode(request, configuration)) {
        return -EINVAL;
    }
    if (!usb_session_policy.Fresh(configuration.header.request_sequence)) {
        return -ESTALE;
    }
    for (size_t i = 0; i < configuration.uart_stop_count; ++i) {
        if (!gateway::UartAvailable(
                configuration.uart_stop_actions[i].channel)) {
            return -ENODEV;
        }
    }
    if (!usb_session_policy.Configure(configuration.lease_us)) {
        return -EINVAL;
    }
    uart_stop_count = configuration.uart_stop_count;
    std::memcpy(uart_stop_actions, configuration.uart_stop_actions.data(),
                sizeof(uart_stop_actions));
    usb_session_policy.Observe(configuration.header.request_sequence);
    return 0;
}

/**
 * @brief 接纳已授权且序号有效的请求，提交成功后续租。
 * @return 接纳成功返回零，否则返回负 errno；接纳不代表硬件传输完成。
 */
int ForwardUsbRequest(const wire::UsbOutRequest& request) {
    const wire::UsbOutRequestView fields(request);
    if (!usb_session_policy.Armed() || usb_session_policy.Expired(NowUs())) {
        return -EACCES;
    }
    if (!usb_session_policy.Fresh(fields.Sequence())) {
        return -ESTALE;
    }
    int result;
    if (fields.MessageKind() == wire::Kind::UartTransmitRequest) {
        wire::UartTransmitRequest uart_request{};
        if (!wire::Decode(request, uart_request)) {
            return -EINVAL;
        }
        result =
            gateway::SubmitUart(uart_request.channel, uart_request.bytes.data(),
                                uart_request.byte_count);
    } else {
        wire::CanTransmitRequest can_request{};
        if (!wire::Decode(request, can_request)) {
            return -EINVAL;
        }
        wire::CanFrame frames[wire::kMaxRecords]{};
        for (size_t i = 0; i < can_request.frame_count; ++i) {
            frames[i] = can_request.frames[i];
            if (!platform::CanAvailable(frames[i].channel)) {
                return -ENODEV;
            }
        }
        result = platform::SubmitCanRecords(frames, can_request.frame_count);
    }
    if (!result && !usb_session_policy.Accept(fields.Sequence(), NowUs())) {
        CloseSession(wire::StopReason::LeaseExpired);
        return -ETIMEDOUT;
    }
    return result;
}

/**
 * @brief 将请求的会话、CAN 或 UART 诊断快照排队发送。
 */
void QueueUsbStatusReply(const wire::UsbOutRequest& request) {
    wire::StatusRequest query{};
    if (!wire::Decode(request, query)) {
        return;
    }
    UsbInPacket reply{};
    if (query.target == wire::StatusTarget::Session) {
        const auto reports = gateway::ReadUsbReportStats();
        platform::UsbTransportStats transport{};
        platform::ReadUsbTransportStats(&transport);
        wire::SessionStatusReport status{};
        status.channel = query.channel;
        status.header.session_id = usb_session_policy.Session();
        status.armed = usb_session_policy.Armed();
        status.configured = usb_session_policy.Configured();
        status.stop_reason = last_stop;
        status.rejected_requests = rejected_usb_requests;
        status.can_report_drops = reports.can_rx_drops;
        status.sensor_report_drops = reports.sensor_report_drops;
        status.stop_errors = stop_errors;
        status.reply_drops = reports.reply_drops;
        status.usb_send_errors = reports.send_errors;
        status.usb_receive_drops = transport.receive_queue_drops;
        status.usb_endpoint_errors = transport.endpoint_errors;
        status.protection_signature = dust::can_profile::kProtectionSignature;
        status.max_lease_us = dust::can_profile::kCommandTimeoutUs;
        wire::Encode(status, reply);
    } else if (query.target == wire::StatusTarget::Can) {
        const auto stats = platform::ReadCanStats(query.channel);
        wire::CanStatusReport status{};
        status.header.session_id = usb_session_policy.Session();
        status.channel = query.channel;
        status.received = stats.received;
        status.submitted = stats.submitted;
        status.completed = stats.completed;
        status.errors = stats.errors;
        status.dropped = stats.dropped;
        status.queue_depth = stats.queue_depth;
        status.controller_state = stats.state;
        status.tx_errors = stats.tx_errors;
        status.rx_errors = stats.rx_errors;
        wire::Encode(status, reply);
    } else {
        const auto stats = gateway::ReadUartStats(query.channel);
        wire::UartStatusReport status{};
        status.header.session_id = usb_session_policy.Session();
        status.channel = query.channel;
        status.received_blocks = stats.received;
        status.dropped_blocks = stats.dropped;
        status.completed_writes = stats.tx_completed;
        status.tx_errors = stats.tx_errors;
        wire::Encode(status, reply);
    }
    gateway::QueueUsbReply(reply);
}

/**
 * @brief 在策略所属线程中校验并分发一次 OUT 传输。
 */
void HandleUsbRequest(const wire::UsbOutRequest& request, size_t length) {
    const wire::UsbOutRequestView fields(request);
    if (!wire::HasHeader(request.data(), length)) {
        ++rejected_usb_requests;
        return;
    }
    const auto kind = fields.MessageKind();
    wire::HelloRequest hello{};
    if (kind == wire::Kind::Hello && length == wire::kOutBytes &&
        wire::Decode(request, hello)) {
        const uint32_t session = hello.header.session_id;
        if (!session) {
            ++rejected_usb_requests;
            return;
        }
        if (usb_session_policy.Session()) {
            CloseSession(wire::StopReason::Replaced);
        }
        usb_session_policy.Open(session);
        usb_connection_epoch = platform::UsbConnectionEpoch();
        gateway::ResetUsbReportQueues();
        gateway::SetUsbReportSession(session);
        wire::ReadyReport ready_report{};
        ready_report.header.session_id = session;
        ready_report.capabilities = usb_report_capabilities;
        ready_report.can_channel_mask = platform::CanChannelMask();
        ready_report.protection_frame_count =
            dust::can_profile::kProtectionFrames.size();
        ready_report.protection_signature =
            dust::can_profile::kProtectionSignature;
        ready_report.max_lease_us = dust::can_profile::kCommandTimeoutUs;
        UsbInPacket ready{};
        wire::Encode(ready_report, ready);
        gateway::QueueUsbReply(ready);
        return;
    }
    if (length != wire::kOutBytes || !usb_session_policy.Session() ||
        fields.Session() != usb_session_policy.Session()) {
        ++rejected_usb_requests;
        return;
    }
    int rc = 0;
    switch (kind) {
        case wire::Kind::ConfigureSafety:
            rc = ConfigureSafety(request);
            QueueUsbRequestResult(request, rc);
            break;
        case wire::Kind::Arm: {
            wire::ArmRequest arm{};
            if (!wire::Decode(request, arm) ||
                !usb_session_policy.Arm(arm.header.request_sequence, NowUs())) {
                rc = -EINVAL;
            }
            QueueUsbRequestResult(request, rc);
            break;
        }
        case wire::Kind::CanTransmitRequest:
        case wire::Kind::UartTransmitRequest:
            rc = ForwardUsbRequest(request);
            // 成功的数据传输不需要 ACK。
            if (rc) {
                QueueUsbRequestResult(request, rc);
            }
            break;
        case wire::Kind::Heartbeat: {
            wire::HeartbeatRequest heartbeat{};
            if (!wire::Decode(request, heartbeat) ||
                !usb_session_policy.Accept(heartbeat.header.request_sequence,
                                           NowUs())) {
                rc = -EINVAL;
            }
            break;
        }
        case wire::Kind::Stop:
            CloseSession(wire::StopReason::Explicit);
            break;
        case wire::Kind::Status: {
            wire::StatusRequest status{};
            if (!wire::Decode(request, status)) {
                rc = -EINVAL;
            } else {
                QueueUsbStatusReply(request);
            }
            break;
        }
        default:
            rc = -ENOTSUP;
            QueueUsbRequestResult(request, rc);
            break;
    }
    if (rc) {
        ++rejected_usb_requests;
    }
    // 队列接纳失败时，必须处理仍获转发授权的控制器，
    // 不能让它静默地继续运行。
    if ((rc == -ENOSPC || rc == -EIO) && usb_session_policy.Armed()) {
        CloseSession(wire::StopReason::TransportError);
    }
}
}  // namespace

namespace gateway {

/**
 * @brief 初始化硬件并运行唯一的策略所有者；初始化失败返回 -1。
 */
int RunGateway() {
    k_thread_priority_set(k_current_get(), kRequestPriority);
    if (platform::InitializeCanPorts(gateway::QueueCanRxForUsb)) {
        return -1;
    }
    if (dust::can_profile::kProtectOnBoot) {
        const auto& frames = dust::can_profile::kProtectionFrames;
        if (platform::ReplaceCanTraffic(frames.data(), frames.size())) {
            ++stop_errors;
        }
    }
    if (platform::InitializeImuHeater() ||
        platform::InitializeBoardIndicators()) {
        return -1;
    }
    usb_report_capabilities =
        1 | gateway::StartUartPorts() | gateway::StartImuReports();
    if (platform::InitializeUsbTransport()) {
        return -1;
    }
    gateway::StartUsbReports();
    uint32_t last_usb_errors = 0;
    uint32_t last_out_drops = 0;
    uint32_t last_endpoint_errors = 0;

    for (;;) {
        // 即使持续收到流量也要检查租约，
        // 畸形数据包不能维持租约。
        if (usb_session_policy.Session() &&
            (!platform::IsUsbConfigured() ||
             platform::UsbConnectionEpoch() != usb_connection_epoch)) {
            CloseSession(wire::StopReason::UsbLost);
        } else if (usb_session_policy.Expired(NowUs())) {
            CloseSession(wire::StopReason::LeaseExpired);
        }
        // 两个读取都会清除锁存故障，必须分别执行，不能短路。
        const bool can_output_fault = platform::TakeCanFault();
        const bool uart_output_fault = gateway::TakeUartFault();
        const bool output_fault = can_output_fault || uart_output_fault;
        if (output_fault && usb_session_policy.Armed()) {
            CloseSession(wire::StopReason::TransportError);
        }
        const uint32_t usb_errors = gateway::ReadUsbReportStats().send_errors;
        platform::UsbTransportStats usb_stats{};
        platform::ReadUsbTransportStats(&usb_stats);
        const bool transport_fault =
            usb_errors != last_usb_errors ||
            usb_stats.receive_queue_drops != last_out_drops ||
            usb_stats.endpoint_errors != last_endpoint_errors;
        if (transport_fault && usb_session_policy.Armed()) {
            CloseSession(wire::StopReason::TransportError);
        }
        last_usb_errors = usb_errors;
        last_out_drops = usb_stats.receive_queue_drops;
        last_endpoint_errors = usb_stats.endpoint_errors;
        platform::SetBoardState(usb_session_policy.Armed(),
                                last_stop == wire::StopReason::TransportError ||
                                    platform::ImuHeaterFaulted());
        wire::UsbOutRequest request{};
        size_t length = 0;
        if (!platform::ReceiveUsb(request.data(), request.size(), &length, 1)) {
            if (usb_session_policy.Session() &&
                platform::UsbConnectionEpoch() != usb_connection_epoch) {
                CloseSession(wire::StopReason::UsbLost);
            }
            if (usb_session_policy.Expired(NowUs())) {
                CloseSession(wire::StopReason::LeaseExpired);
            }
            HandleUsbRequest(request, length);
        }
    }
}

}  // namespace gateway
```

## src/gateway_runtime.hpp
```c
/* SPDX-License-Identifier: Apache-2.0 */

/**
 * @file gateway_runtime.hpp
 * @brief 固件运行入口及所有权约定。
 */
#ifndef DUST_ADAPTER_GATEWAY_RUNTIME_HPP_
#define DUST_ADAPTER_GATEWAY_RUNTIME_HPP_
namespace gateway {

/**
 * @brief 初始化硬件并运行由单一线程拥有的会话请求循环。
 * @details
 * 此线程独占租约和保护策略。回调通过有界队列通信，不得修改策略。启动保护先于
 * USB 初始化。
 * @return 初始化失败返回 -1；成功后不返回。
 */
int RunGateway();
}  // namespace gateway
#endif  // DUST_ADAPTER_GATEWAY_RUNTIME_HPP_
```

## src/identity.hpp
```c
/* SPDX-License-Identifier: Apache-2.0 */

/* 启动身份：直接调用 OTP/NVS 的 Zephyr/HPM API（不再经过端口封装）。
 * 先提交并读回计数，成功后才返回可对外暴露的 boot_id。 */
#pragma once

#include <cstdint>

namespace ecat {

int AllocateBootIdentity(uint64_t& boot);

}  // namespace ecat
```

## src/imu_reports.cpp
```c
/* SPDX-License-Identifier: Apache-2.0 */
#include "imu_reports.hpp"

#include <zephyr/kernel.h>

#include <cstring>

#include "drivers/imu_heater.hpp"
#include "drivers/imu_sensor.hpp"
#include "usb_reports.hpp"
namespace {
namespace wire = dust::wire;
constexpr int kImuPriority = 4;
K_THREAD_STACK_DEFINE(imu_stack, 2048);
k_thread imu_thread;
modules::ImuSensor onboard;

/**
 * @brief 在专用线程中读取原始 IMU 突发数据，发布携带会话标识的数据包。
 */
void ImuLoop(void*, void*, void*) {
    uint32_t sequence = 0;
    for (;;) {
        modules::ImuSensor::Burst burst{};
        if (onboard.TryTakeCompleted(burst)) {
            platform::ObserveImuTemperature(burst.temperature_c);
            wire::UsbInPacket packet{};
            const uint32_t now = k_cyc_to_us_floor64(k_cycle_get_64());
            wire::ImuSampleReport report{};
            report.header.session_id = gateway::CurrentUsbReportSession();
            const uint32_t age =
                k_cyc_to_us_floor32(k_cycle_get_32() - burst.data_ready_cycle);
            report.sample_timestamp_us = now - age;
            report.sample_sequence = sequence++;
            std::memcpy(report.spi_bytes.data(), burst.rx, sizeof(burst.rx));
            report.temperature_c = burst.temperature_c;
            wire::Encode(report, packet);
            gateway::QueueSensorReportForUsb(packet);
        }
        (void)onboard.TryStartAsync();
        k_usleep(100);
    }
}

}  // namespace
namespace gateway {
uint32_t StartImuReports() {
    uint32_t capabilities = 0;
    if (onboard.Init() == 0) {
        capabilities |= 8;
        k_thread_create(&imu_thread, imu_stack,
                        K_THREAD_STACK_SIZEOF(imu_stack), ImuLoop, nullptr,
                        nullptr, nullptr, kImuPriority, 0, K_NO_WAIT);
    }
    return capabilities;
}
}  // namespace gateway
```
